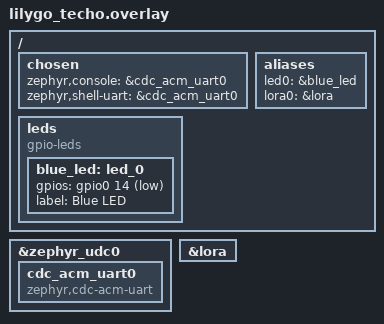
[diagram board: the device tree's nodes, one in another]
/*
 * LilyGo T-Echo device tree overlay for LICHEN bridge
 *
 * nRF52840 + SX1262 LoRa + 1.54" e-ink + L76K GPS
 *
 * SX1262 SPI pins (directly on nRF52):
 *   MOSI  = P0.22
 *   MISO  = P0.23
 *   SCK   = P0.19
 *   NSS   = P0.24
 *
 * SX1262 control pins:
 *   RESET = P0.25
 *   BUSY  = P0.17
 *   DIO1  = P0.20
 *   DIO3  = P0.21 (TCXO control, directly driven by SX1262)
 *
 * E-Ink Display (not enabled - for reference):
 *   MOSI  = P1.06 (38)   DC    = P0.28
 *   MISO  = P0.29        RST   = P0.02
 *   SCK   = P0.31        BUSY  = P0.03
 *   CS    = P0.30        BL    = P1.11 (43)
 *
 * GPS L76K UART (not enabled - for reference):
 *   TX    = P1.08 (40)   PPS   = P1.04 (36)
 *   RX    = P1.09 (41)   WAKE  = P1.02 (34)
 *                        RST   = P1.05 (37)
 *
 * User button: P1.10 (active low)
 * LEDs: Blue P0.14, Green P1.01, Red P1.03 (charger)
 */

/ {
	chosen {
		zephyr,console = &cdc_acm_uart0;
		zephyr,shell-uart = &cdc_acm_uart0;
	};

	aliases {
		led0 = &blue_led;
		lora0 = &lora;
	};

	leds {
		compatible = "gpio-leds";
		blue_led: led_0 {
			gpios = <&gpio0 14 GPIO_ACTIVE_LOW>;
			label = "Blue LED";
		};
	};
};

&zephyr_udc0 {
	cdc_acm_uart0: cdc_acm_uart0 {
		compatible = "zephyr,cdc-acm-uart";
	};
};

&lora {
	status = "okay";
};
